# MSPM0G310X register map
Vendor: Texas Instruments; File version: This preliminary header file does not have a version number - build date: 2023-02-21 16:25:48
CPU: CM0 r0p1, little endian, MPU, no FPU, 3 interrupt priority bits
Registers are 32-bit, read-write, reset 0x0 unless marked. A register's access mark holds for its fields unless they carry their own. Offsets are from the block's base; [hi:lo] are bit positions; {n}, {i} and the like mark numbered series.

## CRC — PERIPHERALREGION
Base 0x40440000
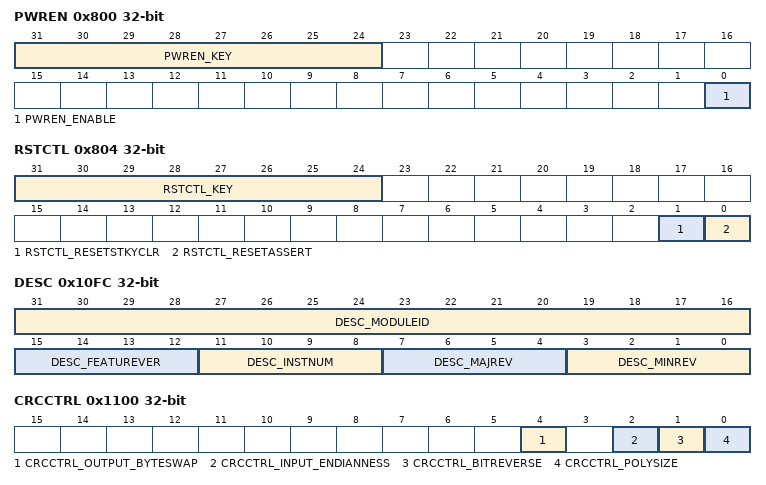
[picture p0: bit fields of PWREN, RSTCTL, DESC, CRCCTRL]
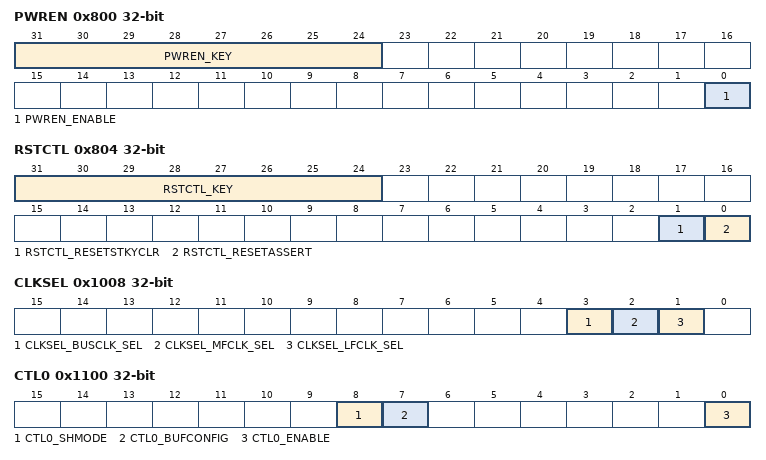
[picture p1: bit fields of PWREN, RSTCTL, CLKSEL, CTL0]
0x800 PWREN — Power enable
  [31:24] PWREN_KEY wo — KEY to allow Power State Change
    38=PWREN_KEY_UNLOCK_W (_TO_UNLOCK_W_)
  [0] PWREN_ENABLE — Enable the power
    0=PWREN_ENABLE_DISABLE (DISABLE); 1=PWREN_ENABLE_ENABLE (ENABLE)
0x804 RSTCTL wo — Reset Control
  [31:24] RSTCTL_KEY — Unlock key
    177=RSTCTL_KEY_UNLOCK_W (_TO_UNLOCK_W_)
  [1] RSTCTL_RESETSTKYCLR — Clear the RESETSTKY bit in the STAT register
    0=RSTCTL_RESETSTKYCLR_NOP (NOP); 1=RSTCTL_RESETSTKYCLR_CLR (CLR)
  [0] RSTCTL_RESETASSERT — Assert reset to the peripheral
    0=RSTCTL_RESETASSERT_NOP (NOP); 1=RSTCTL_RESETASSERT_ASSERT (ASSERT)
0x814 STAT ro — Status Register
  [16] STAT_RESETSTKY — This bit indicates, if the peripheral was reset, since this bit was cleared by RESETSTKYCLR in the RSTCTL register
    0=STAT_RESETSTKY_NORES (NORES); 1=STAT_RESETSTKY_RESET (RESET)
0x10FC DESC ro — Module Description
  [31:16] DESC_MODULEID — Module identification contains a unique peripheral identification number. The assignments are maintained in a central database for all of the platform modules to ensure uniqueness.
  [15:12] DESC_FEATUREVER — Feature Set for the module *instance*
  [11:8] DESC_INSTNUM — Instance Number within the device. This will be a parameter to the RTL for modules that can have multiple instances
  [7:4] DESC_MAJREV — Major rev of the IP
  [3:0] DESC_MINREV — Minor rev of the IP
0x1100 CRCCTRL (reset mask 0x7) — CRC Control Register
  [4] CRCCTRL_OUTPUT_BYTESWAP — CRC Output Byteswap Enable. This bit controls whether the output is byte-swapped upon a read of the CRCOUT register. If CRCOUT is accessed as a half-word, and the OUTPUT_BYTESWAP is set to to 1, then the two bytes in the 16-bit access are swapped and returned. B1 is returned as B0 B0 is returned as B1 If CRCOUT is accessed as a word, and the OUTPUT_BYTESWAP is set to 1, then the four bytes in the 32-bit read are swapped. B3 is returned as B0 B2 is returned as B1 B1 is returned as B2 B0 is returned as B3 Note that if the CRC POLYSIZE is 16-bit and a 32-bit read of CRCOUT is performed with OUTPUT_BYTESWAP enabled, then the output is: MSB LSB 0x0 0x0 B0 B1 If the CRC POLYSIZE is 16-bit and a 32-bit read of CRCOUT is performed with OUTPUT_BYTESWAP disabled, then the output is: MSB LSB 0x0 0x0 B1 B0
    0=CRCCTRL_OUTPUT_BYTESWAP_DISABLE (DISABLE); 1=CRCCTRL_OUTPUT_BYTESWAP_ENABLE (ENABLE)
  [2] CRCCTRL_INPUT_ENDIANNESS — CRC Endian. This bit indicates the byte order within a word or half word of input data.
    0=CRCCTRL_INPUT_ENDIANNESS_LITTLE_ENDIAN (LITTLE_ENDIAN); 1=CRCCTRL_INPUT_ENDIANNESS_BIG_ENDIAN (BIG_ENDIAN)
  [1] CRCCTRL_BITREVERSE — CRC Bit Input and output Reverse. This bit indictes that the bit order of each input byte used for the CRC calculation is reversed before it is passed to the generator, and that the bit order of the calculated CRC is be reversed when read from CRC_RESULT.
    0=CRCCTRL_BITREVERSE_NOT_REVERSED (NOT_REVERSED); 1=CRCCTRL_BITREVERSE_REVERSED (REVERSED)
  [0] CRCCTRL_POLYSIZE — This bit indicates which CRC calculation is performed by the generator.
    0=CRCCTRL_POLYSIZE_CRC32 (CRC32); 1=CRCCTRL_POLYSIZE_CRC16 (CRC16)
0x1104 CRCSEED wo
  [31:0] CRCSEED_SEED — Seed Data
0x1108 CRCIN wo — CRC Input Data Register
  [31:0] CRCIN_DATA — Input Data
0x110C CRCOUT ro — CRC Output Result Register
  [31:0] CRCOUT_RESULT — Result
{0x1800+4i} CRCIN_IDX[{i}] (i=0..511) wo — CRC Input Data Array Register
  [31:0] CRCIN_IDX_DATA — Input Data

## WUC — PERIPHERALREGION
Base 0x40424000
0x400 FSUB_0 — Subscriber Port 0
  [3:0] FSUB_0_CHANID — 0 = disconnected. 1-15 = connected to channelID = CHANID.
    0=FSUB_0_CHANID_UNCONNECTED (UNCONNECTED)
0x404 FSUB_1 — Subscriber Port 1
  [3:0] FSUB_1_CHANID — 0 = disconnected. 1-15 = connected to channelID = CHANID.
    0=FSUB_1_CHANID_UNCONNECTED (UNCONNECTED)

## ADC0_SVT — PERIPHERALREGIONSVT
Base 0x40556000
Same registers: ADC1_SVT 0x40558000
0x160 FIFODATA ro
  [31:0] FIFODATA_DATA — Read from this data field returns the ADC sample from FIFO.
{0x280+4i} MEMRES[{i}] (i=0..11) ro — Memory Result Register
  [15:0] MEMRES_DATA — MEMRES result register. If DF = 0, unsigned binary: The conversion results are right aligned. In 10 and 8 bit modes, the unused MSB bits are forced to 0. If DF = 1, 2s-complement format: The conversion results are left aligned. In 10 and 8 bit modes, the unused LSB bits are forced to 0. The data is stored in the right-justified format and is converted to the left-justified 2s-complement format during read back.

## VREF — PERIPHERALREGION
Base 0x40030000
0x800 PWREN — Power enable
  [31:24] PWREN_KEY wo — KEY to allow Power State Change
    38=PWREN_KEY_UNLOCK_W (_TO_UNLOCK_W_)
  [0] PWREN_ENABLE — Enable the power
    0=PWREN_ENABLE_DISABLE (DISABLE); 1=PWREN_ENABLE_ENABLE (ENABLE)
0x804 RSTCTL wo — Reset Control
  [31:24] RSTCTL_KEY — Unlock key
    177=RSTCTL_KEY_UNLOCK_W (_TO_UNLOCK_W_)
  [1] RSTCTL_RESETSTKYCLR — Clear the RESETSTKY bit in the STAT register
    0=RSTCTL_RESETSTKYCLR_NOP (NOP); 1=RSTCTL_RESETSTKYCLR_CLR (CLR)
  [0] RSTCTL_RESETASSERT — Assert reset to the peripheral
    0=RSTCTL_RESETASSERT_NOP (NOP); 1=RSTCTL_RESETASSERT_ASSERT (ASSERT)
0x814 STAT ro — Status Register
  [16] STAT_RESETSTKY — This bit indicates, if the peripheral was reset, since this bit was cleared by RESETSTKYCLR in the RSTCTL register
    0=STAT_RESETSTKY_NORES (NORES); 1=STAT_RESETSTKY_RESET (RESET)
0x1000 CLKDIV — Clock Divider
  [2:0] CLKDIV_RATIO — Selects divide ratio of module clock to be used in sample and hold logic
0x1008 CLKSEL — Clock Selection
  [3] CLKSEL_BUSCLK_SEL — Selects BUSCLK as clock source if enabled
  [2] CLKSEL_MFCLK_SEL — Selects MFCLK as clock source if enabled
  [1] CLKSEL_LFCLK_SEL — Selects LFCLK as clock source if enabled
0x1100 CTL0 — Control 0
  [8] CTL0_SHMODE — This bit enable sample and hold mode
    0=CTL0_SHMODE_DISABLE (DISABLE); 1=CTL0_SHMODE_ENABLE (ENABLE)
  [7] CTL0_BUFCONFIG — These bits configure output buffer.
    0=CTL0_BUFCONFIG_OUTPUT2P5V (HV); 1=CTL0_BUFCONFIG_OUTPUT1P4V (LV)
  [0] CTL0_ENABLE — This bit enables the VREF module.
    0=CTL0_ENABLE_DISABLE (DISABLE); 1=CTL0_ENABLE_ENABLE (ENABLE)
0x1104 CTL1 — Control 1
  [0] CTL1_READY ro — These bits defines status of VREF
    0=CTL1_READY_NOTRDY (NOTRDY); 1=CTL1_READY_RDY (RDY)
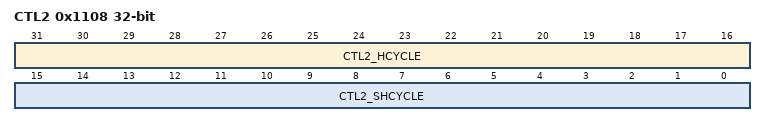
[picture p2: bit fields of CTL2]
0x1108 CTL2 — Control 2
  [31:16] CTL2_HCYCLE — Hold cycle count Total cycles of module clock for hold phase when VREF is working in sample and hold mode in STANDBY to save power. Please refer VREF section of datasheet for recommended values of sample and hold times.
  [15:0] CTL2_SHCYCLE — Sample and Hold cycle count Total cycles of module clock for sample and hold phase when VREF is working in sample and hold mode in STANDBY to save power. This field should be greater than HCYCLE field. The difference between this field and HCYCLE gives the number of cycles of sample phase. Please refer VREF section of datasheet for recommended values of sample and hold times.
